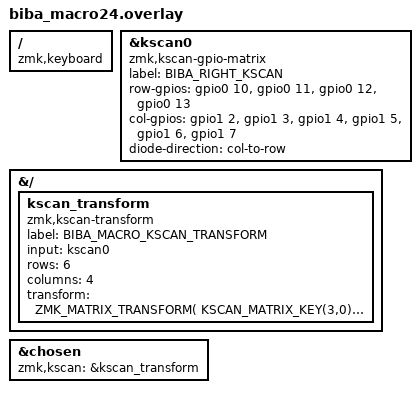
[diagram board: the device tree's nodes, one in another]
/dts-v1/;
/ {
    compatible = "zmk,keyboard";
};

&kscan0 {
    compatible = "zmk,kscan-gpio-matrix";
    label = "BIBA_RIGHT_KSCAN";

    row-gpios = <&gpio0 10 GPIO_ACTIVE_HIGH>,
                <&gpio0 11 GPIO_ACTIVE_HIGH>,
                <&gpio0 12 GPIO_ACTIVE_HIGH>,
                <&gpio0 13 GPIO_ACTIVE_HIGH>;

    col-gpios = <&gpio1 2 GPIO_ACTIVE_HIGH>,
                <&gpio1 3 GPIO_ACTIVE_HIGH>,
                <&gpio1 4 GPIO_ACTIVE_HIGH>,
                <&gpio1 5 GPIO_ACTIVE_HIGH>,
                <&gpio1 6 GPIO_ACTIVE_HIGH>,
                <&gpio1 7 GPIO_ACTIVE_HIGH>;

    diode-direction = "col-to-row";
};

&{/} {
    kscan_transform: kscan_transform {
        compatible = "zmk,kscan-transform";
        label = "BIBA_MACRO_KSCAN_TRANSFORM";
        input = <&kscan0>;
        rows = <6>;
        columns = <4>;

        transform = <ZMK_MATRIX_TRANSFORM(
            KSCAN_MATRIX_KEY(3,0), KSCAN_MATRIX_KEY(2,0), KSCAN_MATRIX_KEY(1,0), KSCAN_MATRIX_KEY(0,0),
            KSCAN_MATRIX_KEY(3,1), KSCAN_MATRIX_KEY(2,1), KSCAN_MATRIX_KEY(1,1), KSCAN_MATRIX_KEY(0,1),
            KSCAN_MATRIX_KEY(3,2), KSCAN_MATRIX_KEY(2,2), KSCAN_MATRIX_KEY(1,2), KSCAN_MATRIX_KEY(0,2),
            KSCAN_MATRIX_KEY(3,3), KSCAN_MATRIX_KEY(2,3), KSCAN_MATRIX_KEY(1,3), KSCAN_MATRIX_KEY(0,3),
            KSCAN_MATRIX_KEY(3,4), KSCAN_MATRIX_KEY(2,4), KSCAN_MATRIX_KEY(1,4), KSCAN_MATRIX_KEY(0,4),
            KSCAN_MATRIX_KEY(3,5), KSCAN_MATRIX_KEY(2,5), KSCAN_MATRIX_KEY(1,5), KSCAN_MATRIX_KEY(0,5)
        )>;
    };
};

&chosen {
    zmk,kscan = &kscan_transform;
};
